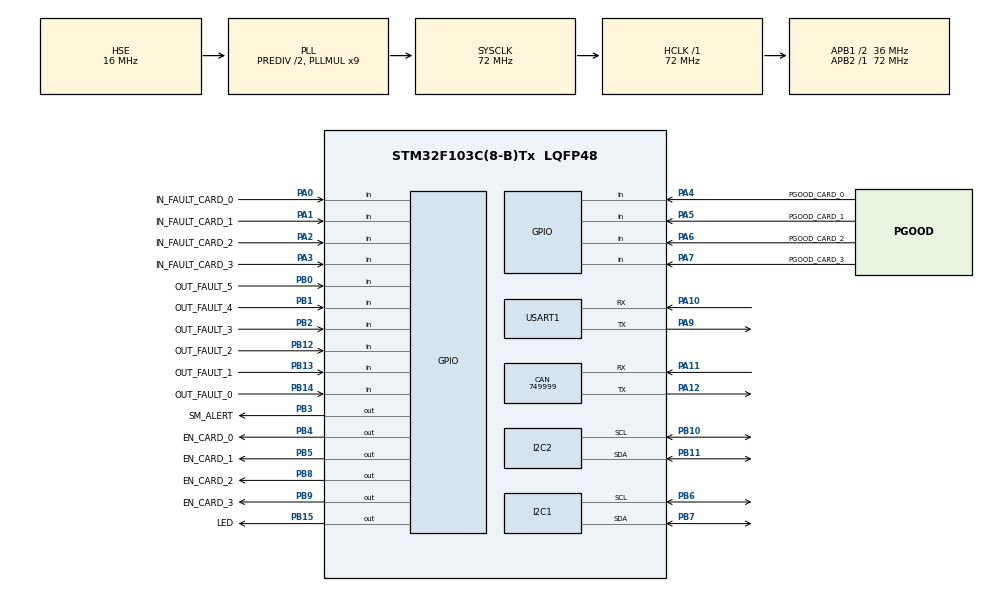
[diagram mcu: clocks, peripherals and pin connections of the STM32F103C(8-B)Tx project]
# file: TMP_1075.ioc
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CAN.CalculateBaudRate=749999
CAN.CalculateTimeBit=1333
CAN.CalculateTimeQuantum=444.44444444444446
Mcu.Family=STM32F1
Mcu.Name=STM32F103C(8-B)Tx
Mcu.Package=LQFP48
NVIC.PriorityGroup=NVIC_PRIORITYGROUP_4
PA0-WKUP.GPIO_Label=IN_FAULT_CARD_0
PA0-WKUP.Signal=GPIO_Input
PA1.GPIO_Label=IN_FAULT_CARD_1
PA1.Signal=GPIO_Input
PA10.Mode=Asynchronous
PA10.Signal=USART1_RX
PA11.Mode=CAN_Activate
PA11.Signal=CAN_RX
PA12.Mode=CAN_Activate
PA12.Signal=CAN_TX
PA13.Mode=Serial_Wire
PA13.Signal=SYS_JTMS-SWDIO
PA14.Mode=Serial_Wire
PA14.Signal=SYS_JTCK-SWCLK
PA2.GPIO_Label=IN_FAULT_CARD_2
PA2.Signal=GPIO_Input
PA3.GPIO_Label=IN_FAULT_CARD_3
PA3.Signal=GPIO_Input
PA4.GPIO_Label=PGOOD_CARD_0
PA4.Signal=GPIO_Input
PA5.GPIO_Label=PGOOD_CARD_1
PA5.Signal=GPIO_Input
PA6.GPIO_Label=PGOOD_CARD_2
PA6.Signal=GPIO_Input
PA7.GPIO_Label=PGOOD_CARD_3
PA7.Signal=GPIO_Input
PA9.Mode=Asynchronous
PA9.Signal=USART1_TX
PB0.GPIO_Label=OUT_FAULT_5
PB0.Signal=GPIO_Input
PB1.GPIO_Label=OUT_FAULT_4
PB1.Signal=GPIO_Input
PB10.Mode=I2C
PB10.Signal=I2C2_SCL
PB11.Mode=I2C
PB11.Signal=I2C2_SDA
PB12.GPIO_Label=OUT_FAULT_2
PB12.Signal=GPIO_Input
PB13.GPIO_Label=OUT_FAULT_1
PB13.Signal=GPIO_Input
PB14.GPIO_Label=OUT_FAULT_0
PB14.Signal=GPIO_Input
PB15.GPIO_Label=LED
PB15.Signal=GPIO_Output
PB2.GPIO_Label=OUT_FAULT_3
PB2.Signal=GPIO_Input
PB3.GPIO_Label=SM_ALERT
PB3.Signal=GPIO_Output
PB4.GPIO_Label=EN_CARD_0
PB4.Signal=GPIO_Output
PB5.GPIO_Label=EN_CARD_1
PB5.Signal=GPIO_Output
PB6.Mode=I2C
PB6.Signal=I2C1_SCL
PB7.Mode=I2C
PB7.Signal=I2C1_SDA
PB8.GPIO_Label=EN_CARD_2
PB8.Signal=GPIO_Output
PB9.GPIO_Label=EN_CARD_3
PB9.Signal=GPIO_Output
PD0-OSC_IN.Mode=HSE-External-Oscillator
PD0-OSC_IN.Signal=RCC_OSC_IN
PD1-OSC_OUT.Mode=HSE-External-Oscillator
PD1-OSC_OUT.Signal=RCC_OSC_OUT
ProjectManager.HeapSize=0x200
ProjectManager.StackSize=0x400
ProjectManager.TargetToolchain=STM32CubeIDE
RCC.AHBFreq_Value=72000000
RCC.APB1CLKDivider=RCC_HCLK_DIV2
RCC.APB1Freq_Value=36000000
RCC.APB1TimFreq_Value=72000000
RCC.APB2Freq_Value=72000000
RCC.APB2TimFreq_Value=72000000
RCC.HCLKFreq_Value=72000000
RCC.HSEDivPLL=RCC_HSE_PREDIV_DIV2
RCC.HSE_VALUE=16000000
RCC.PLLMUL=RCC_PLL_MUL9
RCC.PLLSourceVirtual=RCC_PLLSOURCE_HSE
RCC.SYSCLKFreq_VALUE=72000000
RCC.SYSCLKSource=RCC_SYSCLKSOURCE_PLLCLK
RCC.USBFreq_Value=72000000
USART1.VirtualMode=VM_ASYNC
board=custom

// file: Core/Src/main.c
/* USER CODE BEGIN Header */
/**
  ******************************************************************************
  * @file           : main.c
  * @brief          : Main program body
  ******************************************************************************
  * @attention
  *
  * Copyright (c) 2024 STMicroelectronics.
  * All rights reserved.
  *
  * This software is licensed under terms that can be found in the LICENSE file
  * in the root directory of this software component.
  * If no LICENSE file comes with this software, it is provided AS-IS.
  *
  ******************************************************************************
  */
/* USER CODE END Header */
#include "main.h"
#include "can.h"
#include "i2c.h"
#include "usart.h"
#include "gpio.h"

/* USER CODE BEGIN Includes */
#include "tmp.h"

/* USER CODE END Includes */

void SystemClock_Config(void);

int main(void)
{

  /* MCU Configuration--------------------------------------------------------*/

  /* Reset of all peripherals, Initializes the Flash interface and the Systick. */
  HAL_Init();

  /* USER CODE BEGIN Init */
  HAL_StatusTypeDef i2c_status;
  TMP_1075_StatusTypeDef status;

  /* USER CODE END Init */

  /* Configure the system clock */
  SystemClock_Config();

  /* Initialize all configured peripherals */
  MX_GPIO_Init();
  MX_CAN_Init();
  MX_I2C1_Init();
  MX_I2C2_Init();
  MX_USART1_UART_Init();
  /* USER CODE BEGIN 2 */
  MX_TMP_1075_Init();

  /* USER CODE END 2 */

  /* Infinite loop */
  /* USER CODE BEGIN WHILE */
  uint8_t register_write_buffer = 0b00000100 | 0;
  i2c_status = HAL_I2C_Master_Transmit(&hi2c2, (0b11100000), &register_write_buffer, 1, 1000);

  while (1)
  {
    /* USER CODE END WHILE */

    /* USER CODE BEGIN 3 */

      register_write_buffer = 0b00000100 | 0;
      i2c_status = HAL_I2C_Master_Transmit(&hi2c2, (0b11100000), &register_write_buffer, 1, 1000);

	  status = TMP_1075_ReadTemp(&h_tmp_1075);

	  HAL_GPIO_WritePin(LED_GPIO_Port, LED_Pin, GPIO_PIN_SET);

	  HAL_Delay(1000);

	  HAL_GPIO_WritePin(LED_GPIO_Port, LED_Pin, GPIO_PIN_RESET);

	  HAL_Delay(1000);

  }
  /* USER CODE END 3 */
}

void SystemClock_Config(void)
{
  RCC_OscInitTypeDef RCC_OscInitStruct = {0};
  RCC_ClkInitTypeDef RCC_ClkInitStruct = {0};

  /** Initializes the RCC Oscillators according to the specified parameters
  * in the RCC_OscInitTypeDef structure.
  */
  RCC_OscInitStruct.OscillatorType = RCC_OSCILLATORTYPE_HSE;
  RCC_OscInitStruct.HSEState = RCC_HSE_ON;
  RCC_OscInitStruct.HSEPredivValue = RCC_HSE_PREDIV_DIV2;
  RCC_OscInitStruct.HSIState = RCC_HSI_ON;
  RCC_OscInitStruct.PLL.PLLState = RCC_PLL_ON;
  RCC_OscInitStruct.PLL.PLLSource = RCC_PLLSOURCE_HSE;
  RCC_OscInitStruct.PLL.PLLMUL = RCC_PLL_MUL9;
  if (HAL_RCC_OscConfig(&RCC_OscInitStruct) != HAL_OK)
  {
    Error_Handler();
  }

  /** Initializes the CPU, AHB and APB buses clocks
  */
  RCC_ClkInitStruct.ClockType = RCC_CLOCKTYPE_HCLK|RCC_CLOCKTYPE_SYSCLK
                              |RCC_CLOCKTYPE_PCLK1|RCC_CLOCKTYPE_PCLK2;
  RCC_ClkInitStruct.SYSCLKSource = RCC_SYSCLKSOURCE_PLLCLK;
  RCC_ClkInitStruct.AHBCLKDivider = RCC_SYSCLK_DIV1;
  RCC_ClkInitStruct.APB1CLKDivider = RCC_HCLK_DIV2;
  RCC_ClkInitStruct.APB2CLKDivider = RCC_HCLK_DIV1;

  if (HAL_RCC_ClockConfig(&RCC_ClkInitStruct, FLASH_LATENCY_2) != HAL_OK)
  {
    Error_Handler();
  }
}

void Error_Handler(void)
{
  __disable_irq();
  while (1)
  {
  }
}
